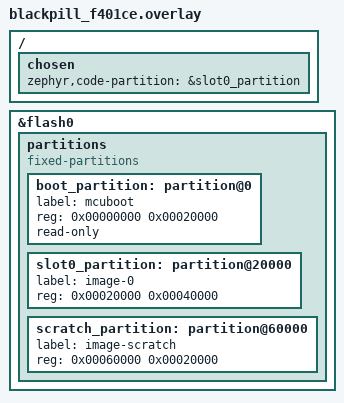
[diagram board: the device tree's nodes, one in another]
/* SPDX-License-Identifier: Apache-2.0 */


/ {
        chosen {
                zephyr,code-partition = &slot0_partition;
        };
};

&flash0 {

	partitions {
		compatible = "fixed-partitions";
		#address-cells = <1>;
		#size-cells = <1>;

		boot_partition: partition@0 {
			label = "mcuboot";
			reg = <0x00000000 0x00020000>;
			read-only;
		};

		slot0_partition: partition@20000 {
			label = "image-0";
			reg = <0x00020000 0x00040000>;
		};

		scratch_partition: partition@60000 {
			label = "image-scratch";
			reg = <0x00060000 0x00020000>;
		};
	};
};
